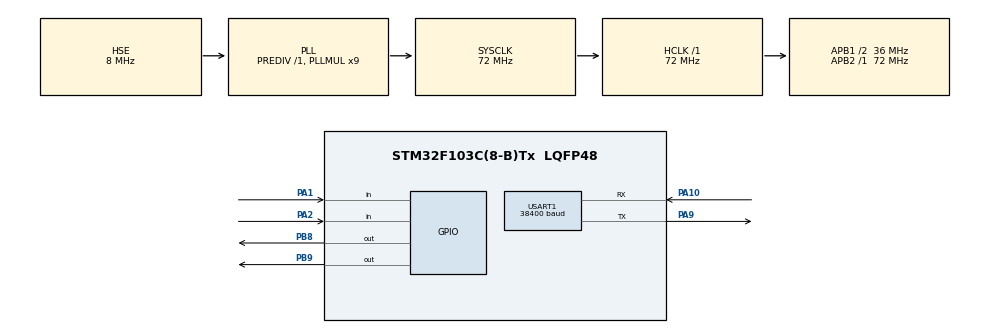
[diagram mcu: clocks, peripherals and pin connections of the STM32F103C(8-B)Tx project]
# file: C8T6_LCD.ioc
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Mcu.Family=STM32F1
Mcu.Name=STM32F103C(8-B)Tx
Mcu.Package=LQFP48
NVIC.PriorityGroup=NVIC_PRIORITYGROUP_4
PA1.Signal=GPIO_Input
PA10.Mode=Asynchronous
PA10.Signal=USART1_RX
PA13.Mode=Serial_Wire
PA13.Signal=SYS_JTMS-SWDIO
PA14.Mode=Serial_Wire
PA14.Signal=SYS_JTCK-SWCLK
PA2.Signal=GPIO_Input
PA9.Mode=Asynchronous
PA9.Signal=USART1_TX
PB8.GPIO_ModeDefaultOutputPP=GPIO_MODE_OUTPUT_OD
PB8.GPIO_PuPd=GPIO_PULLUP
PB8.Signal=GPIO_Output
PB9.GPIO_ModeDefaultOutputPP=GPIO_MODE_OUTPUT_OD
PB9.GPIO_PuPd=GPIO_PULLUP
PB9.Signal=GPIO_Output
PD0-OSC_IN.Mode=HSE-External-Oscillator
PD0-OSC_IN.Signal=RCC_OSC_IN
PD1-OSC_OUT.Mode=HSE-External-Oscillator
PD1-OSC_OUT.Signal=RCC_OSC_OUT
ProjectManager.HeapSize=0x200
ProjectManager.StackSize=0x400
ProjectManager.TargetToolchain=MDK-ARM V5.32
RCC.AHBFreq_Value=72000000
RCC.APB1CLKDivider=RCC_HCLK_DIV2
RCC.APB1Freq_Value=36000000
RCC.APB1TimFreq_Value=72000000
RCC.APB2Freq_Value=72000000
RCC.APB2TimFreq_Value=72000000
RCC.HCLKFreq_Value=72000000
RCC.PLLMUL=RCC_PLL_MUL9
RCC.PLLSourceVirtual=RCC_PLLSOURCE_HSE
RCC.SYSCLKFreq_VALUE=72000000
RCC.SYSCLKSource=RCC_SYSCLKSOURCE_PLLCLK
RCC.USBFreq_Value=72000000
USART1.BaudRate=38400
USART1.VirtualMode=VM_ASYNC
board=custom

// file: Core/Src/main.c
/* USER CODE BEGIN Header */
/**
  ******************************************************************************
  * @file           : main.c
  * @brief          : Main program body
  ******************************************************************************
  * @attention
  *
  * Copyright (c) 2025 STMicroelectronics.
  * All rights reserved.
  *
  * This software is licensed under terms that can be found in the LICENSE file
  * in the root directory of this software component.
  * If no LICENSE file comes with this software, it is provided AS-IS.
  *
  ******************************************************************************
  */
/* USER CODE END Header */
#include "main.h"
#include "usart.h"
#include "gpio.h"

/* USER CODE BEGIN Includes */
#include "string.h"
#include "stdio.h"
#include "oled.h"

#include "stm32f1xx.h"
#include "Delay.h"
#include "MyIIC.h"
#include "MLX90614.h"
#include "MLX90614_Address.h"
#include "bmp.h"

/* USER CODE END Includes */

/* USER CODE BEGIN PD */
char ambient_temp_str[20];
char object_temp_str[20];
/* USER CODE END PD */

/* USER CODE BEGIN PV */
//printf

/* USER CODE END PV */

void SystemClock_Config(void);

int main(void)
{

  /* MCU Configuration--------------------------------------------------------*/

  /* Reset of all peripherals, Initializes the Flash interface and the Systick. */
  HAL_Init();

  /* Configure the system clock */
  SystemClock_Config();

  /* Initialize all configured peripherals */
  MX_GPIO_Init();
  MX_USART1_UART_Init();
  /* USER CODE BEGIN 2 */

	Delay_ms(1000);

  /* USER CODE END 2 */

  /* Infinite loop */
  /* USER CODE BEGIN WHILE */
/* ???? */
/* USER CODE BEGIN WHILE */
MLX90614_Init();
OLED_Init();
Delay_ms(20);

float ambient_temperature = 0;
float object_temperature = 0;
int mode = 0; // 0=???, 1=OLED????, 2=????

// ????
for(int i=0;i<2;i++){
	OLED_DrawGIF(32,0,96,8,18,512,Rocket);
  Delay_ms(100);
}

// ?????,???????
OLED_Clear();
OLED_ShowString(1, 1, "1:OLED Mode");
OLED_ShowString(2, 1, "2:Bluetooth Mode");

while (1)
{
  if (mode == 0) // ---------- ???????? ----------
  {
    // ?????,????????????

    // ??PA1,????????
    if (HAL_GPIO_ReadPin(GPIOA, GPIO_PIN_1) == GPIO_PIN_RESET)
    {
      Delay_ms(20);
      if (HAL_GPIO_ReadPin(GPIOA, GPIO_PIN_1) == GPIO_PIN_RESET)
      {
        mode = 1; // ?????1
        // ????1?,??????
        OLED_Clear();
        OLED_ShowString(1, 1, "OLED Mode Ready");
        OLED_ShowString(2, 1, "1:Read temp");
        OLED_ShowString(3, 1, "2:Menu");
        while (HAL_GPIO_ReadPin(GPIOA, GPIO_PIN_1) == GPIO_PIN_RESET); // ??????
      }
    }

    // ??PA2,????????
    if (HAL_GPIO_ReadPin(GPIOA, GPIO_PIN_2) == GPIO_PIN_RESET)
    {
      Delay_ms(20);
      if (HAL_GPIO_ReadPin(GPIOA, GPIO_PIN_2) == GPIO_PIN_RESET)
      {
        mode = 2; // ?????2
        OLED_Clear();
        OLED_ShowString(1, 1, "Bluetooth Mode");
        OLED_ShowString(2, 1, "Sending data...");
        while (HAL_GPIO_ReadPin(GPIOA, GPIO_PIN_2) == GPIO_PIN_RESET); // ??????
      }
    }
  }
  else if (mode == 1) // ---------- ???OLED???? ----------
  {
    // ???1?,???????????????????

    // ??PA1,??????????
    if (HAL_GPIO_ReadPin(GPIOA, GPIO_PIN_1) == GPIO_PIN_RESET)
    {
      Delay_ms(20);
      if (HAL_GPIO_ReadPin(GPIOA, GPIO_PIN_1) == GPIO_PIN_RESET)
      {
        // --- ??????????? ---
        MLX90614_TA();
        Delay_ms(20);
        MLX90614_TO();
        Delay_ms(20);

        ambient_temperature = a_temp;
        object_temperature = o_temp;

        snprintf(ambient_temp_str, sizeof(ambient_temp_str), "Amb: %.2f C", ambient_temperature*1.08);
        snprintf(object_temp_str, sizeof(object_temp_str), "Obj: %.2f C", object_temperature*1.05);

        OLED_Clear();
        OLED_ShowString(1, 1, "Reading:");
        OLED_ShowString(2, 1, ambient_temp_str);
        OLED_ShowString(3, 1, object_temp_str);
        // --- ??????? ---

        while (HAL_GPIO_ReadPin(GPIOA, GPIO_PIN_1) == GPIO_PIN_RESET); // ??????
      }
    }

    // ??PA2,?????????
    if (HAL_GPIO_ReadPin(GPIOA, GPIO_PIN_2) == GPIO_PIN_RESET)
    {
      Delay_ms(20);
      if (HAL_GPIO_ReadPin(GPIOA, GPIO_PIN_2) == GPIO_PIN_RESET)
      {
        mode = 0; // ????????
        OLED_Clear();
        OLED_ShowString(1, 1, "1:OLED Mode");
        OLED_ShowString(2, 1, "2:Bluetooth Mode");
        while (HAL_GPIO_ReadPin(GPIOA, GPIO_PIN_2) == GPIO_PIN_RESET); // ??????
      }
    }
  }
  else if (mode == 2) // ---------- ??????? ----------
  {
				OLED_Clear();
        MLX90614_TA();
        Delay_ms(20);
        MLX90614_TO();
        Delay_ms(20);

        object_temperature = o_temp;
        snprintf(object_temp_str, sizeof(object_temp_str), "temp: %.2f C\r\n", object_temperature);

        HAL_UART_Transmit(&huart1, (uint8_t *)object_temp_str, strlen(object_temp_str), HAL_MAX_DELAY);

        OLED_ShowString(1, 1, "Data Sent!");
        Delay_ms(500); // ??????
  }

  // ?????
  Delay_ms(50);
}
/* USER CODE END 3 */
}

void SystemClock_Config(void)
{
  RCC_OscInitTypeDef RCC_OscInitStruct = {0};
  RCC_ClkInitTypeDef RCC_ClkInitStruct = {0};

  /** Initializes the RCC Oscillators according to the specified parameters
  * in the RCC_OscInitTypeDef structure.
  */
  RCC_OscInitStruct.OscillatorType = RCC_OSCILLATORTYPE_HSE;
  RCC_OscInitStruct.HSEState = RCC_HSE_ON;
  RCC_OscInitStruct.HSEPredivValue = RCC_HSE_PREDIV_DIV1;
  RCC_OscInitStruct.HSIState = RCC_HSI_ON;
  RCC_OscInitStruct.PLL.PLLState = RCC_PLL_ON;
  RCC_OscInitStruct.PLL.PLLSource = RCC_PLLSOURCE_HSE;
  RCC_OscInitStruct.PLL.PLLMUL = RCC_PLL_MUL9;
  if (HAL_RCC_OscConfig(&RCC_OscInitStruct) != HAL_OK)
  {
    Error_Handler();
  }

  /** Initializes the CPU, AHB and APB buses clocks
  */
  RCC_ClkInitStruct.ClockType = RCC_CLOCKTYPE_HCLK|RCC_CLOCKTYPE_SYSCLK
                              |RCC_CLOCKTYPE_PCLK1|RCC_CLOCKTYPE_PCLK2;
  RCC_ClkInitStruct.SYSCLKSource = RCC_SYSCLKSOURCE_PLLCLK;
  RCC_ClkInitStruct.AHBCLKDivider = RCC_SYSCLK_DIV1;
  RCC_ClkInitStruct.APB1CLKDivider = RCC_HCLK_DIV2;
  RCC_ClkInitStruct.APB2CLKDivider = RCC_HCLK_DIV1;

  if (HAL_RCC_ClockConfig(&RCC_ClkInitStruct, FLASH_LATENCY_2) != HAL_OK)
  {
    Error_Handler();
  }
}

void Error_Handler(void)
{
  __disable_irq();
  while (1)
  {
  }
}
